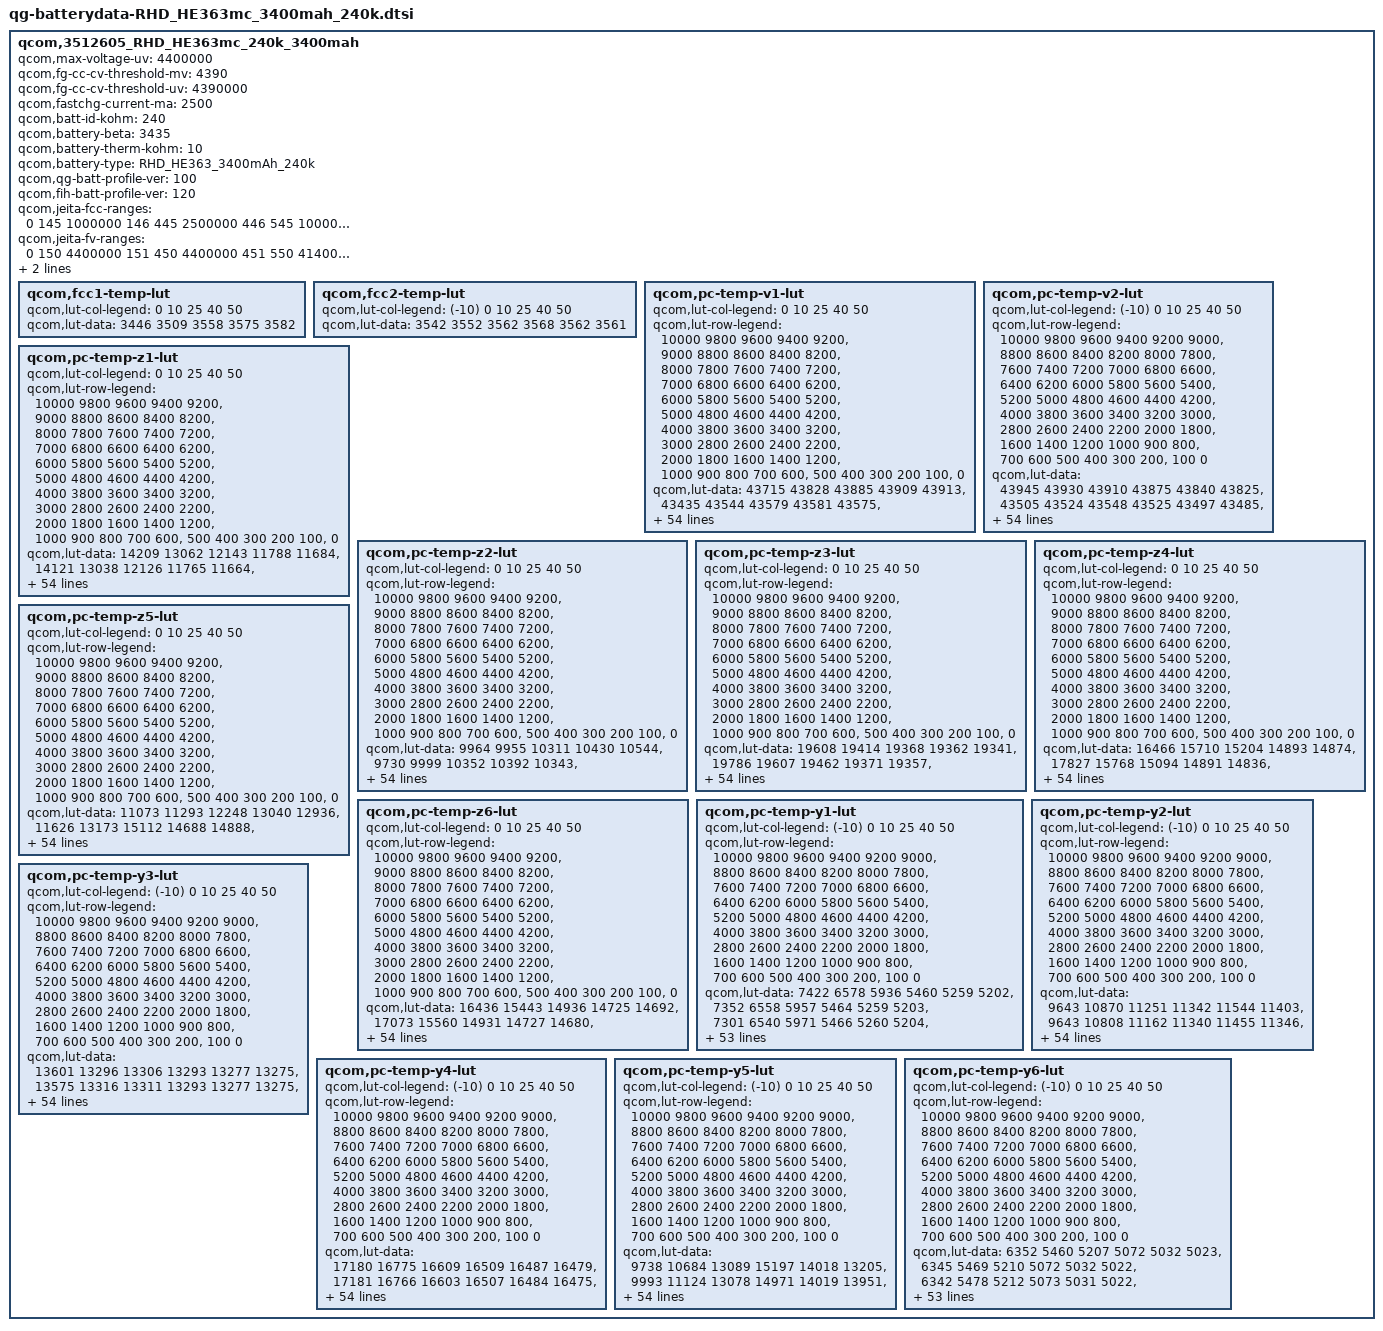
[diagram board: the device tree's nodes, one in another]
qcom,3512605_RHD_HE363mc_240k_3400mah {
	/* 3512605_FIH_HE363mc_3400mAh_averaged_MasterSlave_Jun25th2018 */
	qcom,max-voltage-uv = <4400000>;
	qcom,fg-cc-cv-threshold-mv = <4390>; // not use
	qcom,fg-cc-cv-threshold-uv = <4390000>; // not use
	qcom,fastchg-current-ma = <2500>;
	qcom,batt-id-kohm = <240>;
	qcom,battery-beta = <3435>;
	qcom,battery-therm-kohm = <10>;
	qcom,battery-type =
		"RHD_HE363_3400mAh_240k";
	qcom,qg-batt-profile-ver = <100>;
	qcom,fih-batt-profile-ver = <120>;

	qcom,jeita-fcc-ranges = <0   145   1000000
				 146 445  2500000
				 446 545  1000000
				 546 550  100000>;
	qcom,jeita-fv-ranges =  <0   150  4400000
				 151 450  4400000
				 451 550  4140000>;

	qcom,jeita-soft-thresholds = <0x257d 0xfb3>;
	qcom,jeita-hard-thresholds = <0x3733 0xbc2>;

	qcom,fcc1-temp-lut {
		qcom,lut-col-legend = <0 10 25 40 50>;
		qcom,lut-data = <3446 3509 3558 3575 3582>;
	};

	qcom,fcc2-temp-lut {
		qcom,lut-col-legend = <(-10) 0 10 25 40 50>;
		qcom,lut-data = <3542 3552 3562 3568 3562 3561>;
	};

	qcom,pc-temp-v1-lut {
		qcom,lut-col-legend = <0 10 25 40 50>;
		qcom,lut-row-legend = <10000 9800 9600 9400 9200>,
			<9000 8800 8600 8400 8200>,
			<8000 7800 7600 7400 7200>,
			<7000 6800 6600 6400 6200>,
			<6000 5800 5600 5400 5200>,
			<5000 4800 4600 4400 4200>,
			<4000 3800 3600 3400 3200>,
			<3000 2800 2600 2400 2200>,
			<2000 1800 1600 1400 1200>,
			<1000 900 800 700 600>,
			<500 400 300 200 100>,
			<0>;
		qcom,lut-data = <43715 43828 43885 43909 43913>,
			<43435 43544 43579 43581 43575>,
			<43142 43252 43304 43306 43301>,
			<42859 42997 43045 43054 43049>,
			<42605 42753 42799 42813 42810>,
			<42369 42511 42557 42575 42574>,
			<42142 42277 42319 42338 42340>,
			<41926 42049 42085 42104 42110>,
			<41715 41828 41855 41875 41881>,
			<41504 41612 41630 41649 41655>,
			<41297 41395 41408 41425 41432>,
			<41112 41189 41190 41205 41214>,
			<40953 41012 40985 40990 41000>,
			<40772 40854 40805 40787 40793>,
			<40486 40651 40625 40589 40591>,
			<40167 40344 40408 40396 40396>,
			<39972 40072 40172 40206 40208>,
			<39846 39933 39985 40027 40030>,
			<39732 39831 39843 39861 39861>,
			<39618 39708 39706 39703 39699>,
			<39506 39566 39567 39555 39549>,
			<39387 39418 39418 39408 39402>,
			<39260 39273 39212 39220 39219>,
			<39137 39119 38931 38968 38977>,
			<39022 38935 38736 38767 38776>,
			<38910 38719 38630 38643 38643>,
			<38795 38565 38547 38541 38535>,
			<38680 38471 38463 38441 38432>,
			<38577 38400 38387 38349 38338>,
			<38484 38341 38314 38267 38252>,
			<38404 38292 38243 38195 38175>,
			<38339 38247 38180 38130 38104>,
			<38284 38204 38129 38072 38043>,
			<38241 38164 38083 38019 37986>,
			<38209 38131 38043 37973 37935>,
			<38180 38099 38006 37933 37890>,
			<38152 38067 37968 37890 37840>,
			<38125 38038 37931 37841 37782>,
			<38087 37999 37886 37783 37716>,
			<38025 37931 37815 37708 37638>,
			<37944 37837 37717 37616 37546>,
			<37833 37730 37610 37509 37440>,
			<37691 37599 37485 37380 37313>,
			<37533 37442 37335 37232 37163>,
			<37372 37286 37178 37081 37011>,
			<37244 37172 37071 36978 36917>,
			<37201 37134 37043 36951 36890>,
			<37169 37107 37021 36931 36871>,
			<37144 37085 37003 36917 36857>,
			<37117 37061 36978 36889 36822>,
			<37005 36938 36834 36714 36622>,
			<36629 36559 36444 36313 36210>,
			<36076 36002 35883 35757 35650>,
			<35315 35240 35116 34998 34886>,
			<34135 34062 33929 33841 33713>,
			<30000 30000 30000 30000 30000>;
	};

	qcom,pc-temp-v2-lut {
		qcom,lut-col-legend = <(-10) 0 10 25 40 50>;
		qcom,lut-row-legend = <10000 9800 9600 9400 9200 9000>,
			<8800 8600 8400 8200 8000 7800>,
			<7600 7400 7200 7000 6800 6600>,
			<6400 6200 6000 5800 5600 5400>,
			<5200 5000 4800 4600 4400 4200>,
			<4000 3800 3600 3400 3200 3000>,
			<2800 2600 2400 2200 2000 1800>,
			<1600 1400 1200 1000 900 800>,
			<700 600 500 400 300 200>,
			<100 0>;
		qcom,lut-data = <43945 43930 43910 43875 43840 43825>,
			<43505 43524 43548 43525 43497 43485>,
			<43121 43169 43223 43209 43187 43177>,
			<42801 42872 42941 42934 42914 42906>,
			<42529 42621 42694 42691 42673 42666>,
			<42276 42378 42453 42453 42437 42430>,
			<42043 42138 42213 42216 42202 42196>,
			<41811 41905 41979 41983 41970 41964>,
			<41544 41681 41754 41755 41742 41736>,
			<41266 41463 41536 41530 41516 41511>,
			<41067 41257 41318 41306 41295 41290>,
			<40942 41066 41101 41085 41077 41072>,
			<40787 40865 40893 40875 40864 40860>,
			<40453 40645 40711 40689 40661 40654>,
			<40038 40407 40527 40505 40463 40453>,
			<39754 40123 40288 40292 40270 40262>,
			<39532 39795 40004 40061 40082 40078>,
			<39343 39560 39779 39871 39904 39901>,
			<39181 39418 39616 39726 39738 39733>,
			<39033 39289 39458 39576 39575 39568>,
			<38881 39124 39265 39390 39413 39411>,
			<38732 38949 39062 39187 39248 39252>,
			<38596 38794 38889 38987 39051 39057>,
			<38468 38651 38736 38785 38814 38816>,
			<38354 38524 38600 38619 38623 38621>,
			<38254 38410 38480 38493 38493 38492>,
			<38167 38307 38372 38385 38385 38385>,
			<38097 38208 38273 38286 38285 38284>,
			<38037 38114 38183 38197 38196 38193>,
			<37985 38033 38101 38116 38115 38110>,
			<37941 37963 38027 38042 38042 38036>,
			<37899 37903 37957 37973 37974 37967>,
			<37854 37855 37893 37910 37915 37907>,
			<37807 37815 37835 37850 37857 37848>,
			<37758 37778 37788 37794 37795 37783>,
			<37708 37745 37748 37740 37729 37712>,
			<37653 37707 37707 37684 37654 37629>,
			<37594 37663 37665 37627 37566 37521>,
			<37528 37610 37617 37563 37476 37414>,
			<37457 37550 37555 37486 37397 37329>,
			<37381 37476 37479 37401 37319 37252>,
			<37302 37367 37387 37317 37230 37166>,
			<37221 37247 37274 37199 37119 37056>,
			<37133 37131 37144 37072 36996 36930>,
			<37036 37020 36993 36918 36844 36783>,
			<36926 36930 36929 36874 36804 36748>,
			<36866 36889 36904 36864 36793 36737>,
			<36800 36848 36876 36846 36779 36724>,
			<36713 36787 36850 36815 36753 36697>,
			<36596 36693 36788 36740 36689 36624>,
			<36379 36483 36569 36467 36448 36355>,
			<36007 36065 36096 35965 35976 35871>,
			<35420 35439 35448 35305 35345 35230>,
			<34527 34559 34532 34370 34462 34345>,
			<33056 33144 33219 33097 33217 33037>,
			<28780 28512 28416 28775 29593 29393>;
	};

	qcom,pc-temp-z1-lut {
		qcom,lut-col-legend = <0 10 25 40 50>;
		qcom,lut-row-legend = <10000 9800 9600 9400 9200>,
			<9000 8800 8600 8400 8200>,
			<8000 7800 7600 7400 7200>,
			<7000 6800 6600 6400 6200>,
			<6000 5800 5600 5400 5200>,
			<5000 4800 4600 4400 4200>,
			<4000 3800 3600 3400 3200>,
			<3000 2800 2600 2400 2200>,
			<2000 1800 1600 1400 1200>,
			<1000 900 800 700 600>,
			<500 400 300 200 100>,
			<0>;
		qcom,lut-data = <14209 13062 12143 11788 11684>,
			<14121 13038 12126 11765 11664>,
			<14152 13003 12110 11758 11661>,
			<14179 12999 12103 11751 11657>,
			<14171 12997 12095 11748 11656>,
			<14146 12985 12088 11746 11655>,
			<14124 12970 12083 11745 11654>,
			<14103 12967 12079 11744 11654>,
			<14084 12967 12079 11743 11653>,
			<14066 12967 12079 11742 11652>,
			<14046 12966 12080 11741 11651>,
			<14026 12965 12084 11741 11651>,
			<14003 12959 12086 11741 11651>,
			<13985 12947 12080 11740 11651>,
			<13974 12937 12072 11740 11653>,
			<13963 12921 12067 11740 11653>,
			<13937 12910 12065 11740 11654>,
			<13879 12913 12065 11740 11655>,
			<13846 12922 12070 11742 11655>,
			<13846 12932 12076 11743 11656>,
			<13846 12949 12081 11745 11657>,
			<13849 12962 12085 11746 11658>,
			<13863 12972 12089 11748 11660>,
			<13880 12981 12093 11751 11662>,
			<13904 12982 12098 11754 11665>,
			<13925 12980 12103 11758 11668>,
			<13931 12982 12108 11761 11671>,
			<13933 12989 12116 11765 11674>,
			<13939 12997 12125 11769 11676>,
			<13981 13004 12130 11773 11679>,
			<14031 13011 12132 11775 11681>,
			<14049 13015 12135 11778 11683>,
			<14060 13019 12140 11780 11685>,
			<14068 13024 12145 11784 11687>,
			<14075 13031 12150 11787 11689>,
			<14081 13039 12155 11790 11692>,
			<14079 13051 12161 11793 11694>,
			<14070 13071 12168 11796 11696>,
			<14066 13083 12175 11799 11698>,
			<14051 13086 12180 11802 11701>,
			<14039 13090 12184 11805 11703>,
			<14039 13104 12189 11808 11705>,
			<14040 13128 12196 11809 11707>,
			<14022 13127 12202 11812 11709>,
			<13996 13114 12209 11816 11711>,
			<13987 13106 12215 11818 11713>,
			<14035 13108 12211 11819 11713>,
			<14074 13103 12210 11820 11713>,
			<14035 13103 12213 11822 11714>,
			<13970 13106 12217 11826 11718>,
			<13970 13118 12227 11833 11723>,
			<14020 13131 12238 11840 11730>,
			<13999 13164 12251 11850 11741>,
			<14043 13196 12281 11866 11754>,
			<14043 13196 12281 11866 11754>,
			<14043 13196 12281 11866 11754>;
	};

	qcom,pc-temp-z2-lut {
		qcom,lut-col-legend = <0 10 25 40 50>;
		qcom,lut-row-legend = <10000 9800 9600 9400 9200>,
			<9000 8800 8600 8400 8200>,
			<8000 7800 7600 7400 7200>,
			<7000 6800 6600 6400 6200>,
			<6000 5800 5600 5400 5200>,
			<5000 4800 4600 4400 4200>,
			<4000 3800 3600 3400 3200>,
			<3000 2800 2600 2400 2200>,
			<2000 1800 1600 1400 1200>,
			<1000 900 800 700 600>,
			<500 400 300 200 100>,
			<0>;
		qcom,lut-data = <9964 9955 10311 10430 10544>,
			<9730 9999 10352 10392 10343>,
			<9829 10040 10374 10515 10356>,
			<9882 10025 10348 10513 10510>,
			<9879 10010 10318 10470 10470>,
			<9869 9999 10298 10453 10444>,
			<9866 9989 10284 10470 10448>,
			<9865 9981 10277 10493 10452>,
			<9863 9968 10296 10503 10454>,
			<9857 9959 10333 10510 10461>,
			<9848 9952 10348 10517 10462>,
			<9838 9949 10355 10526 10432>,
			<9827 9977 10366 10531 10404>,
			<9818 10057 10404 10493 10387>,
			<9815 10091 10442 10436 10367>,
			<9814 10056 10433 10430 10377>,
			<9819 10026 10406 10440 10415>,
			<9837 10055 10402 10451 10438>,
			<9848 10105 10436 10477 10445>,
			<9848 10131 10470 10499 10453>,
			<9846 10142 10489 10507 10474>,
			<9844 10155 10504 10513 10508>,
			<9838 10182 10514 10534 10552>,
			<9835 10211 10521 10611 10665>,
			<9844 10220 10515 10649 10722>,
			<9862 10223 10482 10662 10682>,
			<9880 10229 10454 10670 10615>,
			<9903 10244 10458 10638 10546>,
			<9923 10258 10472 10582 10469>,
			<9940 10259 10471 10546 10436>,
			<9956 10258 10444 10504 10424>,
			<9968 10259 10427 10480 10419>,
			<9978 10267 10432 10491 10411>,
			<9990 10278 10442 10517 10400>,
			<10003 10289 10458 10550 10427>,
			<10016 10301 10487 10596 10512>,
			<9979 10314 10510 10637 10577>,
			<9875 10329 10525 10667 10617>,
			<9834 10346 10540 10698 10651>,
			<9757 10366 10564 10745 10682>,
			<9691 10387 10590 10795 10710>,
			<9722 10408 10604 10816 10718>,
			<9777 10429 10612 10820 10720>,
			<9789 10448 10624 10770 10718>,
			<9705 10557 10650 10707 10715>,
			<9578 10921 10723 10786 10735>,
			<9605 11029 10727 10748 10743>,
			<9616 11117 10727 10731 10738>,
			<9637 11167 10774 10793 10787>,
			<9637 11187 10874 10879 10937>,
			<9782 11256 10921 10801 10711>,
			<9669 10931 10941 10664 10482>,
			<9506 10665 10901 10576 10398>,
			<9327 10426 10830 10472 10297>,
			<9327 10426 10830 10472 10297>,
			<9327 10426 10830 10472 10297>;
	};

	qcom,pc-temp-z3-lut {
		qcom,lut-col-legend = <0 10 25 40 50>;
		qcom,lut-row-legend = <10000 9800 9600 9400 9200>,
			<9000 8800 8600 8400 8200>,
			<8000 7800 7600 7400 7200>,
			<7000 6800 6600 6400 6200>,
			<6000 5800 5600 5400 5200>,
			<5000 4800 4600 4400 4200>,
			<4000 3800 3600 3400 3200>,
			<3000 2800 2600 2400 2200>,
			<2000 1800 1600 1400 1200>,
			<1000 900 800 700 600>,
			<500 400 300 200 100>,
			<0>;
		qcom,lut-data = <19608 19414 19368 19362 19341>,
			<19786 19607 19462 19371 19357>,
			<19898 19749 19493 19394 19368>,
			<19953 19779 19536 19441 19420>,
			<19953 19788 19537 19442 19425>,
			<19939 19783 19537 19442 19425>,
			<19937 19773 19530 19439 19420>,
			<19942 19763 19521 19433 19411>,
			<19946 19753 19507 19424 19405>,
			<19951 19746 19490 19413 19399>,
			<19957 19739 19482 19406 19395>,
			<19957 19732 19479 19403 19386>,
			<19947 19717 19474 19400 19378>,
			<19937 19694 19455 19385 19372>,
			<19933 19687 19436 19368 19365>,
			<19929 19680 19440 19366 19362>,
			<19914 19664 19451 19366 19358>,
			<19869 19625 19453 19366 19355>,
			<19825 19571 19444 19364 19352>,
			<19791 19563 19436 19361 19350>,
			<19763 19589 19434 19359 19346>,
			<19755 19610 19432 19357 19343>,
			<19769 19617 19439 19359 19344>,
			<19782 19623 19466 19372 19350>,
			<19785 19631 19478 19379 19358>,
			<19788 19643 19458 19373 19366>,
			<19805 19648 19439 19367 19373>,
			<19854 19646 19442 19377 19379>,
			<19884 19642 19452 19402 19385>,
			<19893 19636 19458 19409 19387>,
			<19895 19629 19469 19402 19382>,
			<19889 19623 19475 19395 19376>,
			<19877 19619 19470 19391 19371>,
			<19862 19615 19461 19386 19365>,
			<19841 19610 19455 19381 19359>,
			<19811 19603 19451 19374 19352>,
			<19747 19597 19448 19371 19348>,
			<19644 19590 19445 19369 19346>,
			<19572 19583 19443 19368 19345>,
			<19464 19575 19440 19366 19345>,
			<19383 19565 19436 19364 19345>,
			<19377 19551 19432 19363 19344>,
			<19374 19533 19426 19362 19342>,
			<19360 19525 19423 19358 19342>,
			<19316 19480 19420 19351 19343>,
			<19271 19321 19395 19347 19335>,
			<19271 19311 19383 19340 19329>,
			<19270 19302 19376 19338 19328>,
			<19269 19296 19363 19327 19316>,
			<19269 19291 19351 19320 19311>,
			<19265 19298 19356 19339 19336>,
			<19268 19306 19354 19350 19347>,
			<19272 19306 19343 19354 19351>,
			<19294 19304 19340 19358 19351>,
			<19294 19304 19340 19358 19351>,
			<19294 19304 19340 19358 19351>;
	};

	qcom,pc-temp-z4-lut {
		qcom,lut-col-legend = <0 10 25 40 50>;
		qcom,lut-row-legend = <10000 9800 9600 9400 9200>,
			<9000 8800 8600 8400 8200>,
			<8000 7800 7600 7400 7200>,
			<7000 6800 6600 6400 6200>,
			<6000 5800 5600 5400 5200>,
			<5000 4800 4600 4400 4200>,
			<4000 3800 3600 3400 3200>,
			<3000 2800 2600 2400 2200>,
			<2000 1800 1600 1400 1200>,
			<1000 900 800 700 600>,
			<500 400 300 200 100>,
			<0>;
		qcom,lut-data = <16466 15710 15204 14893 14874>,
			<17827 15768 15094 14891 14836>,
			<17637 16170 15047 14832 14787>,
			<17350 15843 15149 14930 14864>,
			<17016 15516 15030 14881 14827>,
			<16608 15358 14944 14835 14792>,
			<16300 15240 14891 14803 14773>,
			<16066 15150 14856 14781 14760>,
			<15880 15080 14836 14773 14752>,
			<15740 15025 14821 14769 14745>,
			<15628 14980 14812 14763 14741>,
			<15519 14942 14806 14752 14736>,
			<15404 14897 14799 14745 14733>,
			<15339 14846 14790 14747 14730>,
			<15329 14833 14781 14750 14724>,
			<15323 14865 14774 14747 14719>,
			<15298 14894 14767 14736 14712>,
			<15218 14890 14758 14727 14706>,
			<15160 14879 14746 14721 14700>,
			<15145 14860 14737 14716 14696>,
			<15134 14817 14733 14714 14695>,
			<15117 14789 14731 14713 14695>,
			<15087 14785 14756 14730 14710>,
			<15064 14784 14857 14819 14794>,
			<15047 14809 14901 14867 14844>,
			<15031 14894 14899 14862 14828>,
			<15006 14932 14893 14849 14800>,
			<14954 14924 14873 14822 14775>,
			<14922 14911 14831 14775 14750>,
			<14911 14895 14799 14750 14734>,
			<14905 14872 14771 14739 14725>,
			<14900 14851 14753 14732 14718>,
			<14894 14832 14745 14723 14711>,
			<14888 14815 14739 14717 14706>,
			<14882 14800 14734 14714 14705>,
			<14875 14787 14729 14713 14706>,
			<14908 14773 14726 14712 14707>,
			<14993 14760 14723 14718 14717>,
			<15028 14751 14721 14724 14726>,
			<15105 14746 14723 14726 14726>,
			<15172 14743 14725 14727 14725>,
			<15162 14743 14723 14724 14722>,
			<15141 14744 14709 14712 14712>,
			<15130 14737 14702 14712 14711>,
			<15095 14756 14695 14714 14711>,
			<15050 14872 14677 14686 14686>,
			<15046 14877 14680 14681 14680>,
			<15041 14880 14674 14663 14661>,
			<15032 14879 14679 14655 14647>,
			<15020 14877 14685 14653 14642>,
			<15012 14870 14694 14660 14648>,
			<15039 14879 14708 14660 14650>,
			<15066 14891 14725 14660 14650>,
			<15080 14908 14736 14660 14652>,
			<15080 14908 14736 14660 14652>,
			<15080 14908 14736 14660 14652>;
	};

	qcom,pc-temp-z5-lut {
		qcom,lut-col-legend = <0 10 25 40 50>;
		qcom,lut-row-legend = <10000 9800 9600 9400 9200>,
			<9000 8800 8600 8400 8200>,
			<8000 7800 7600 7400 7200>,
			<7000 6800 6600 6400 6200>,
			<6000 5800 5600 5400 5200>,
			<5000 4800 4600 4400 4200>,
			<4000 3800 3600 3400 3200>,
			<3000 2800 2600 2400 2200>,
			<2000 1800 1600 1400 1200>,
			<1000 900 800 700 600>,
			<500 400 300 200 100>,
			<0>;
		qcom,lut-data = <11073 11293 12248 13040 12936>,
			<11626 13173 15112 14688 14888>,
			<12253 13406 16286 17076 17039>,
			<12794 13862 15715 17018 18322>,
			<13160 14338 16238 17244 19096>,
			<13461 14661 16698 17578 19666>,
			<13763 14957 17167 18300 19993>,
			<14076 15305 17440 18919 20113>,
			<14374 15704 17449 18701 19954>,
			<14661 16139 17432 18056 19621>,
			<14934 16716 17500 17899 19541>,
			<15139 17296 17699 18206 19155>,
			<15319 17765 17762 18422 18746>,
			<15431 18297 17069 17536 18392>,
			<15422 18482 16303 16259 17981>,
			<15364 18189 16608 16234 18046>,
			<15326 17627 17643 16790 18302>,
			<15180 16614 18607 17293 18551>,
			<15023 15400 19563 17668 18911>,
			<14751 15580 20258 18011 19244>,
			<14394 18533 20624 18321 19394>,
			<14356 22013 21036 18642 19495>,
			<15086 25098 23738 19140 19433>,
			<16042 28161 31845 20087 18899>,
			<16937 31403 35038 20500 18257>,
			<17988 35631 27606 18137 17133>,
			<20045 37188 20090 15468 16092>,
			<23915 34726 19466 16217 16513>,
			<26515 31385 19620 18825 18160>,
			<28549 29269 20572 20358 19505>,
			<30163 27532 23978 21151 20448>,
			<30330 26843 26485 21918 21374>,
			<29930 26694 27034 23208 22525>,
			<29255 26747 27433 24666 23621>,
			<27255 26899 28286 25368 24222>,
			<24525 27081 29575 25799 24639>,
			<21573 27294 30255 26002 24731>,
			<18282 27561 30616 25989 24078>,
			<16255 27622 30767 25812 23169>,
			<13537 27350 30295 24813 22465>,
			<11596 26791 29320 23181 21783>,
			<11581 24834 28429 22924 21217>,
			<11630 21427 27561 23244 20742>,
			<11564 21312 27321 22032 20374>,
			<11454 19655 27318 20180 20310>,
			<11383 12308 25296 21556 20472>,
			<11369 12087 21383 20083 19158>,
			<11362 11929 19637 20999 20514>,
			<11373 11839 17643 19424 20109>,
			<11398 11793 16165 18277 19525>,
			<11443 12002 16766 19731 22097>,
			<11398 11994 16228 19670 21942>,
			<11253 11873 14468 19436 21404>,
			<11215 11713 13916 19200 20154>,
			<11215 11713 13916 19200 20154>,
			<11215 11713 13916 19200 20154>;
	};

	qcom,pc-temp-z6-lut {
		qcom,lut-col-legend = <0 10 25 40 50>;
		qcom,lut-row-legend = <10000 9800 9600 9400 9200>,
			<9000 8800 8600 8400 8200>,
			<8000 7800 7600 7400 7200>,
			<7000 6800 6600 6400 6200>,
			<6000 5800 5600 5400 5200>,
			<5000 4800 4600 4400 4200>,
			<4000 3800 3600 3400 3200>,
			<3000 2800 2600 2400 2200>,
			<2000 1800 1600 1400 1200>,
			<1000 900 800 700 600>,
			<500 400 300 200 100>,
			<0>;
		qcom,lut-data = <16436 15443 14936 14725 14692>,
			<17073 15560 14931 14727 14680>,
			<17020 15787 14924 14713 14665>,
			<16932 15657 14989 14780 14724>,
			<16793 15521 14938 14760 14712>,
			<16594 15444 14899 14739 14698>,
			<16447 15383 14873 14724 14686>,
			<16340 15336 14852 14711 14676>,
			<16255 15299 14834 14702 14668>,
			<16192 15269 14819 14694 14663>,
			<16141 15246 14811 14687 14657>,
			<16085 15224 14807 14682 14651>,
			<16024 15194 14801 14676 14646>,
			<15975 15158 14785 14669 14640>,
			<15946 15147 14770 14661 14634>,
			<15922 15147 14769 14657 14629>,
			<15881 15147 14770 14653 14624>,
			<15814 15130 14768 14649 14620>,
			<15766 15098 14759 14645 14616>,
			<15744 15090 14751 14642 14613>,
			<15731 15089 14749 14640 14611>,
			<15731 15089 14748 14638 14609>,
			<15734 15091 14763 14647 14616>,
			<15738 15096 14822 14693 14658>,
			<15740 15113 14848 14718 14682>,
			<15743 15158 14840 14714 14680>,
			<15748 15177 14828 14708 14674>,
			<15756 15176 14819 14702 14669>,
			<15763 15172 14809 14695 14662>,
			<15770 15165 14802 14688 14655>,
			<15776 15152 14796 14681 14649>,
			<15775 15142 14791 14673 14642>,
			<15772 15134 14784 14667 14637>,
			<15767 15127 14778 14662 14631>,
			<15758 15120 14774 14658 14627>,
			<15747 15113 14771 14653 14623>,
			<15735 15108 14768 14652 14622>,
			<15722 15104 14766 14654 14625>,
			<15708 15101 14765 14656 14628>,
			<15693 15098 14765 14656 14628>,
			<15681 15096 14766 14656 14628>,
			<15675 15093 14764 14654 14627>,
			<15670 15088 14757 14650 14621>,
			<15660 15085 14753 14647 14621>,
			<15627 15073 14750 14645 14622>,
			<15586 15049 14732 14630 14607>,
			<15585 15046 14726 14625 14601>,
			<15582 15043 14720 14617 14593>,
			<15581 15043 14716 14607 14581>,
			<15578 15042 14715 14604 14576>,
			<15584 15048 14723 14617 14592>,
			<15607 15065 14732 14625 14601>,
			<15638 15083 14738 14629 14605>,
			<15675 15107 14749 14635 14610>,
			<15675 15107 14749 14635 14610>,
			<15675 15107 14749 14635 14610>;
	};

	qcom,pc-temp-y1-lut {
		qcom,lut-col-legend = <(-10) 0 10 25 40 50>;
		qcom,lut-row-legend = <10000 9800 9600 9400 9200 9000>,
			<8800 8600 8400 8200 8000 7800>,
			<7600 7400 7200 7000 6800 6600>,
			<6400 6200 6000 5800 5600 5400>,
			<5200 5000 4800 4600 4400 4200>,
			<4000 3800 3600 3400 3200 3000>,
			<2800 2600 2400 2200 2000 1800>,
			<1600 1400 1200 1000 900 800>,
			<700 600 500 400 300 200>,
			<100 0>;
		qcom,lut-data = <7422 6578 5936 5460 5259 5202>,
			<7352 6558 5957 5464 5259 5203>,
			<7301 6540 5971 5466 5260 5204>,
			<7265 6526 5980 5467 5260 5206>,
			<7243 6517 5984 5467 5260 5206>,
			<7232 6514 5984 5466 5260 5207>,
			<7242 6517 5977 5463 5260 5207>,
			<7254 6521 5968 5461 5260 5207>,
			<7248 6518 5964 5461 5258 5207>,
			<7234 6512 5962 5460 5255 5207>,
			<7225 6508 5961 5460 5255 5207>,
			<7211 6506 5962 5460 5257 5206>,
			<7202 6504 5962 5459 5258 5206>,
			<7204 6520 5961 5456 5258 5205>,
			<7208 6542 5960 5454 5258 5205>,
			<7213 6544 5962 5456 5258 5204>,
			<7225 6535 5966 5462 5259 5204>,
			<7230 6531 5967 5466 5259 5204>,
			<7218 6531 5966 5467 5261 5205>,
			<7205 6531 5966 5467 5263 5206>,
			<7217 6532 5967 5466 5263 5207>,
			<7246 6533 5968 5465 5263 5209>,
			<7257 6532 5968 5465 5264 5209>,
			<7255 6528 5967 5467 5264 5211>,
			<7254 6526 5967 5470 5265 5212>,
			<7249 6531 5968 5473 5265 5213>,
			<7239 6537 5969 5476 5266 5213>,
			<7229 6536 5974 5478 5268 5214>,
			<7213 6530 5984 5481 5271 5214>,
			<7202 6526 5987 5484 5273 5216>,
			<7191 6526 5984 5489 5275 5219>,
			<7183 6529 5982 5493 5277 5221>,
			<7187 6527 5987 5495 5280 5222>,
			<7198 6524 5996 5497 5283 5222>,
			<7203 6527 5998 5499 5284 5223>,
			<7205 6539 5998 5500 5285 5227>,
			<7205 6544 5999 5502 5286 5229>,
			<7194 6542 6003 5508 5289 5230>,
			<7180 6538 6007 5512 5292 5231>,
			<7182 6533 6002 5512 5293 5233>,
			<7192 6530 5996 5511 5293 5235>,
			<7210 6535 6001 5515 5296 5238>,
			<7218 6540 5998 5518 5298 5238>,
			<7175 6543 5999 5519 5297 5239>,
			<7202 6543 6011 5522 5301 5241>,
			<7226 6566 6012 5523 5305 5241>,
			<7188 6544 6017 5529 5304 5242>,
			<7196 6545 6011 5530 5306 5241>,
			<7220 6561 6014 5533 5306 5243>,
			<7214 6550 6025 5536 5305 5243>,
			<7214 6556 6027 5539 5305 5245>,
			<7191 6581 6042 5545 5312 5247>,
			<7200 6565 6056 5559 5321 5253>,
			<7261 6581 6077 5580 5330 5262>,
			<7261 6581 6077 5580 5330 5262>,
			<7261 6581 6077 5580 5330 5262>;
	};

	qcom,pc-temp-y2-lut {
		qcom,lut-col-legend = <(-10) 0 10 25 40 50>;
		qcom,lut-row-legend = <10000 9800 9600 9400 9200 9000>,
			<8800 8600 8400 8200 8000 7800>,
			<7600 7400 7200 7000 6800 6600>,
			<6400 6200 6000 5800 5600 5400>,
			<5200 5000 4800 4600 4400 4200>,
			<4000 3800 3600 3400 3200 3000>,
			<2800 2600 2400 2200 2000 1800>,
			<1600 1400 1200 1000 900 800>,
			<700 600 500 400 300 200>,
			<100 0>;
		qcom,lut-data = <9643 10870 11251 11342 11544 11403>,
			<9643 10808 11162 11340 11455 11346>,
			<9643 10733 11076 11320 11348 11278>,
			<9777 10660 10997 11288 11246 11211>,
			<9919 10601 10927 11248 11171 11155>,
			<9999 10569 10868 11203 11143 11123>,
			<10167 10553 10818 11138 11147 11102>,
			<10317 10544 10776 11082 11155 11088>,
			<10318 10549 10742 11050 11150 11078>,
			<10304 10562 10714 11020 11135 11064>,
			<10322 10570 10698 11014 11117 11042>,
			<10479 10573 10687 11001 11059 10996>,
			<10586 10578 10682 10983 11025 10970>,
			<10572 10626 10690 10958 11021 11000>,
			<10534 10692 10709 10937 11018 11037>,
			<10369 10718 10736 10939 11021 11033>,
			<9917 10731 10780 10957 11035 11012>,
			<9714 10746 10816 10986 11053 11009>,
			<9704 10768 10840 11048 11076 11013>,
			<9698 10791 10865 11095 11109 11021>,
			<9690 10811 10903 11104 11191 11106>,
			<9682 10831 10949 11110 11292 11237>,
			<9678 10857 10995 11131 11303 11257>,
			<9675 10891 11043 11185 11273 11242>,
			<9673 10915 11083 11220 11259 11236>,
			<9672 10926 11115 11230 11294 11270>,
			<9671 10936 11136 11239 11333 11317>,
			<9670 10959 11141 11256 11339 11349>,
			<9668 11002 11143 11278 11340 11387>,
			<9666 11034 11144 11287 11333 11428>,
			<9665 11058 11139 11299 11324 11481>,
			<9663 11070 11137 11306 11320 11520>,
			<9662 11061 11141 11301 11381 11540>,
			<9660 11037 11144 11292 11467 11551>,
			<9659 11005 11140 11283 11452 11546>,
			<9658 10957 11132 11272 11366 11513>,
			<9657 10910 11122 11259 11325 11473>,
			<9656 10871 11100 11238 11328 11413>,
			<9655 10833 11080 11224 11331 11371>,
			<9654 10795 11081 11328 11329 11379>,
			<9653 10745 11082 11448 11334 11400>,
			<9653 10339 11040 11267 11371 11403>,
			<9652 9859 11018 11334 11372 11396>,
			<9652 9761 11018 11319 11329 11412>,
			<9652 9708 11066 11342 11345 11387>,
			<9652 9677 10902 11251 11353 11245>,
			<9652 9669 10849 11192 11313 11191>,
			<9651 9664 10789 11206 11260 11139>,
			<9652 9661 10702 11195 11228 11117>,
			<9651 9658 10651 11176 11192 11094>,
			<9651 9656 10586 11152 11202 11024>,
			<9651 9654 10492 11055 11145 10972>,
			<9651 9652 10364 10967 11016 10861>,
			<9650 9651 10216 10827 10857 10684>,
			<9650 9651 10216 10827 10857 10684>,
			<9650 9651 10216 10827 10857 10684>;
	};

	qcom,pc-temp-y3-lut {
		qcom,lut-col-legend = <(-10) 0 10 25 40 50>;
		qcom,lut-row-legend = <10000 9800 9600 9400 9200 9000>,
			<8800 8600 8400 8200 8000 7800>,
			<7600 7400 7200 7000 6800 6600>,
			<6400 6200 6000 5800 5600 5400>,
			<5200 5000 4800 4600 4400 4200>,
			<4000 3800 3600 3400 3200 3000>,
			<2800 2600 2400 2200 2000 1800>,
			<1600 1400 1200 1000 900 800>,
			<700 600 500 400 300 200>,
			<100 0>;
		qcom,lut-data = <13601 13296 13306 13293 13277 13275>,
			<13575 13316 13311 13293 13277 13275>,
			<13560 13336 13315 13293 13278 13276>,
			<13553 13354 13318 13293 13278 13277>,
			<13551 13369 13319 13294 13279 13278>,
			<13552 13381 13320 13294 13279 13278>,
			<13561 13390 13318 13294 13280 13279>,
			<13571 13398 13316 13294 13280 13279>,
			<13571 13407 13322 13294 13280 13280>,
			<13570 13415 13334 13296 13280 13280>,
			<13564 13422 13343 13296 13280 13280>,
			<13537 13430 13349 13296 13280 13280>,
			<13515 13433 13355 13297 13280 13280>,
			<13511 13433 13362 13301 13284 13280>,
			<13507 13431 13367 13307 13288 13279>,
			<13493 13423 13367 13310 13288 13281>,
			<13457 13403 13365 13313 13287 13284>,
			<13442 13394 13362 13315 13287 13286>,
			<13442 13393 13357 13315 13290 13285>,
			<13442 13392 13351 13315 13293 13285>,
			<13438 13387 13344 13314 13295 13288>,
			<13429 13377 13338 13311 13297 13293>,
			<13419 13368 13331 13306 13295 13291>,
			<13405 13358 13324 13300 13286 13281>,
			<13393 13353 13320 13297 13280 13275>,
			<13386 13354 13318 13296 13278 13275>,
			<13382 13355 13317 13295 13277 13275>,
			<13386 13351 13317 13295 13277 13274>,
			<13401 13338 13318 13295 13278 13274>,
			<13419 13333 13319 13295 13278 13274>,
			<13444 13331 13320 13295 13279 13275>,
			<13473 13331 13321 13296 13280 13276>,
			<13501 13330 13320 13296 13280 13276>,
			<13530 13329 13319 13296 13280 13276>,
			<13568 13332 13320 13296 13280 13275>,
			<13619 13343 13321 13296 13280 13276>,
			<13682 13352 13322 13297 13280 13276>,
			<13765 13357 13324 13298 13279 13274>,
			<13868 13361 13325 13298 13278 13273>,
			<13988 13365 13323 13290 13278 13274>,
			<14134 13371 13320 13281 13278 13274>,
			<14311 13353 13323 13295 13277 13276>,
			<14511 13349 13321 13289 13278 13276>,
			<14547 13358 13322 13290 13279 13276>,
			<14735 13378 13303 13284 13278 13274>,
			<15054 13384 13317 13286 13279 13277>,
			<15236 13430 13318 13293 13281 13279>,
			<15396 13501 13322 13297 13285 13284>,
			<15540 13580 13344 13299 13287 13286>,
			<15702 13710 13360 13305 13291 13287>,
			<15850 13875 13367 13299 13285 13283>,
			<16032 14110 13372 13299 13286 13283>,
			<16286 14603 13396 13311 13293 13288>,
			<17209 15267 13440 13318 13295 13291>,
			<17209 15267 13440 13318 13295 13291>,
			<17209 15267 13440 13318 13295 13291>;
	};

	qcom,pc-temp-y4-lut {
		qcom,lut-col-legend = <(-10) 0 10 25 40 50>;
		qcom,lut-row-legend = <10000 9800 9600 9400 9200 9000>,
			<8800 8600 8400 8200 8000 7800>,
			<7600 7400 7200 7000 6800 6600>,
			<6400 6200 6000 5800 5600 5400>,
			<5200 5000 4800 4600 4400 4200>,
			<4000 3800 3600 3400 3200 3000>,
			<2800 2600 2400 2200 2000 1800>,
			<1600 1400 1200 1000 900 800>,
			<700 600 500 400 300 200>,
			<100 0>;
		qcom,lut-data = <17180 16775 16609 16509 16487 16479>,
			<17181 16766 16603 16507 16484 16475>,
			<17202 16763 16602 16507 16482 16471>,
			<17229 16764 16606 16508 16481 16468>,
			<17252 16769 16612 16509 16480 16466>,
			<17260 16774 16621 16511 16480 16466>,
			<17267 16783 16638 16516 16482 16466>,
			<17269 16796 16653 16521 16484 16468>,
			<17244 16818 16655 16526 16487 16470>,
			<17206 16851 16657 16531 16492 16472>,
			<17244 16878 16661 16538 16497 16476>,
			<17592 16898 16677 16549 16504 16481>,
			<17829 16925 16699 16561 16509 16486>,
			<17563 17005 16748 16574 16512 16492>,
			<17170 17087 16798 16589 16514 16499>,
			<17107 17040 16808 16602 16521 16504>,
			<17114 16854 16812 16616 16535 16507>,
			<17118 16778 16810 16638 16550 16513>,
			<17112 16779 16793 16689 16566 16526>,
			<17102 16780 16765 16723 16586 16544>,
			<17084 16760 16713 16713 16621 16573>,
			<17055 16720 16643 16688 16660 16605>,
			<17031 16702 16608 16642 16644 16595>,
			<17008 16694 16588 16555 16545 16524>,
			<16993 16686 16577 16508 16490 16483>,
			<16987 16673 16571 16497 16483 16477>,
			<16983 16661 16567 16492 16480 16475>,
			<16979 16663 16563 16493 16481 16476>,
			<16976 16671 16560 16495 16483 16479>,
			<16973 16673 16558 16498 16487 16483>,
			<16967 16667 16558 16503 16494 16490>,
			<16963 16662 16559 16508 16503 16497>,
			<16967 16667 16558 16514 16516 16510>,
			<16975 16676 16556 16519 16528 16523>,
			<16980 16677 16556 16519 16529 16524>,
			<16983 16672 16557 16515 16524 16523>,
			<16984 16670 16558 16510 16515 16519>,
			<16985 16677 16559 16500 16490 16493>,
			<16986 16690 16560 16492 16469 16469>,
			<16989 16700 16565 16497 16470 16469>,
			<16996 16712 16570 16503 16473 16471>,
			<17006 16757 16566 16490 16480 16476>,
			<17014 16784 16569 16497 16479 16476>,
			<16996 16762 16554 16493 16478 16475>,
			<16995 16764 16576 16487 16458 16451>,
			<17032 16820 16570 16496 16468 16465>,
			<17063 16839 16588 16499 16482 16478>,
			<17100 16870 16614 16516 16498 16498>,
			<17143 16941 16647 16546 16525 16530>,
			<17187 17030 16716 16568 16546 16544>,
			<17197 17079 16745 16543 16505 16489>,
			<17181 17088 16729 16546 16489 16479>,
			<17178 17134 16788 16589 16505 16492>,
			<17452 17284 16907 16707 16561 16552>,
			<17452 17284 16907 16707 16561 16552>,
			<17452 17284 16907 16707 16561 16552>;
	};

	qcom,pc-temp-y5-lut {
		qcom,lut-col-legend = <(-10) 0 10 25 40 50>;
		qcom,lut-row-legend = <10000 9800 9600 9400 9200 9000>,
			<8800 8600 8400 8200 8000 7800>,
			<7600 7400 7200 7000 6800 6600>,
			<6400 6200 6000 5800 5600 5400>,
			<5200 5000 4800 4600 4400 4200>,
			<4000 3800 3600 3400 3200 3000>,
			<2800 2600 2400 2200 2000 1800>,
			<1600 1400 1200 1000 900 800>,
			<700 600 500 400 300 200>,
			<100 0>;
		qcom,lut-data = <9738 10684 13089 15197 14018 13205>,
			<9993 11124 13078 14971 14019 13951>,
			<10561 11583 12978 14685 13994 14531>,
			<11244 12018 12816 14396 13949 14939>,
			<11847 12383 12615 14161 13888 15170>,
			<12200 12631 12389 14019 13816 15214>,
			<12857 12785 11978 13666 13730 15014>,
			<13429 12930 11678 13335 13620 14747>,
			<13251 13143 11859 13229 13454 14557>,
			<12773 13394 12300 13085 13223 14354>,
			<12591 13602 12567 12913 12977 14112>,
			<12633 13795 12728 12595 12678 13821>,
			<12828 14069 12865 12434 12542 13520>,
			<14329 14792 12970 12537 12957 13150>,
			<16275 15568 13100 12701 13478 12860>,
			<15708 15673 13644 12863 13376 13008>,
			<12713 15557 14844 13109 12931 13527>,
			<11399 15565 15551 13325 12783 13686>,
			<11432 15906 15941 13479 12925 13343>,
			<11469 16181 16138 13712 13187 13059>,
			<11437 15953 16098 14959 13882 13666>,
			<11334 15365 15980 16687 14906 14753>,
			<11244 14768 15696 16948 15397 14903>,
			<11124 14038 14913 16828 15621 14637>,
			<10997 13709 14432 16796 15641 14502>,
			<10836 13928 14344 16933 15198 14814>,
			<10697 14191 14341 17070 14791 15169>,
			<10683 13906 14435 17044 14896 15084>,
			<10693 12961 14658 16927 15114 14785>,
			<10716 12529 14934 16916 15359 14739>,
			<10859 12460 15273 17122 15666 15171>,
			<10991 12437 15401 17338 15962 15479>,
			<10981 12382 15224 17595 16174 15399>,
			<10945 12310 15113 17916 16384 15259>,
			<10938 12467 15293 18160 16843 15512>,
			<10993 13249 15632 18397 17752 16638>,
			<11036 13892 15899 18804 18121 17166>,
			<11083 14279 16180 19874 17888 17018>,
			<11143 14536 16372 20678 17512 16773>,
			<11135 14669 15828 17148 17063 16422>,
			<11103 14908 15042 12895 16452 16106>,
			<11118 13000 15332 18537 15560 16621>,
			<11192 11680 14730 15799 15517 16289>,
			<11093 11517 15200 16161 16120 16010>,
			<11185 11453 12525 13625 17110 17494>,
			<11183 11084 13389 13740 15926 15700>,
			<11254 11204 13111 15745 15233 15147>,
			<11431 11469 13002 16139 15586 15820>,
			<11561 11471 14698 15121 15097 15080>,
			<12008 11790 15296 15769 15219 14769>,
			<12077 12069 15273 15089 14698 15296>,
			<11879 11862 15278 15221 16169 15924>,
			<11420 11624 15314 17281 18372 17829>,
			<10772 11405 14994 17029 17928 18249>,
			<10772 11405 14994 17029 17928 18249>,
			<10772 11405 14994 17029 17928 18249>;
	};

	qcom,pc-temp-y6-lut {
		qcom,lut-col-legend = <(-10) 0 10 25 40 50>;
		qcom,lut-row-legend = <10000 9800 9600 9400 9200 9000>,
			<8800 8600 8400 8200 8000 7800>,
			<7600 7400 7200 7000 6800 6600>,
			<6400 6200 6000 5800 5600 5400>,
			<5200 5000 4800 4600 4400 4200>,
			<4000 3800 3600 3400 3200 3000>,
			<2800 2600 2400 2200 2000 1800>,
			<1600 1400 1200 1000 900 800>,
			<700 600 500 400 300 200>,
			<100 0>;
		qcom,lut-data = <6352 5460 5207 5072 5032 5023>,
			<6345 5469 5210 5072 5032 5022>,
			<6342 5478 5212 5073 5031 5022>,
			<6342 5487 5215 5073 5031 5021>,
			<6343 5494 5217 5074 5032 5022>,
			<6344 5500 5220 5075 5032 5022>,
			<6348 5505 5221 5076 5033 5022>,
			<6350 5510 5223 5078 5034 5023>,
			<6335 5518 5228 5080 5035 5024>,
			<6303 5530 5234 5082 5037 5026>,
			<6303 5539 5241 5085 5038 5027>,
			<6364 5547 5249 5088 5040 5028>,
			<6405 5556 5258 5092 5042 5030>,
			<6339 5576 5276 5098 5045 5031>,
			<6232 5595 5292 5107 5049 5033>,
			<6186 5577 5294 5113 5052 5036>,
			<6159 5513 5294 5119 5055 5039>,
			<6150 5486 5292 5127 5059 5042>,
			<6150 5487 5283 5142 5066 5046>,
			<6150 5487 5270 5151 5073 5051>,
			<6149 5480 5251 5147 5085 5061>,
			<6148 5465 5227 5137 5096 5073>,
			<6149 5456 5212 5120 5091 5069>,
			<6153 5449 5203 5091 5056 5040>,
			<6159 5447 5197 5076 5035 5024>,
			<6170 5448 5195 5072 5032 5022>,
			<6185 5449 5194 5071 5030 5022>,
			<6203 5450 5195 5071 5031 5022>,
			<6225 5451 5196 5072 5032 5023>,
			<6249 5452 5198 5073 5033 5024>,
			<6277 5455 5200 5075 5036 5027>,
			<6308 5459 5203 5077 5039 5030>,
			<6342 5465 5204 5080 5044 5034>,
			<6382 5474 5205 5082 5048 5037>,
			<6427 5484 5207 5082 5048 5037>,
			<6480 5498 5210 5082 5047 5037>,
			<6542 5515 5213 5081 5044 5036>,
			<6616 5532 5216 5080 5037 5028>,
			<6704 5552 5220 5078 5030 5021>,
			<6805 5576 5222 5074 5030 5021>,
			<6922 5605 5224 5070 5031 5022>,
			<7061 5628 5229 5076 5033 5025>,
			<7213 5662 5232 5075 5034 5025>,
			<7239 5671 5231 5075 5034 5025>,
			<7382 5725 5230 5070 5028 5017>,
			<7624 5832 5247 5075 5032 5023>,
			<7761 5917 5259 5082 5037 5028>,
			<7889 6021 5276 5089 5045 5038>,
			<8008 6140 5311 5100 5055 5048>,
			<8132 6298 5355 5111 5063 5053>,
			<8246 6467 5386 5101 5047 5035>,
			<8380 6675 5409 5104 5044 5032>,
			<8577 7078 5492 5129 5055 5041>,
			<9425 7619 5644 5173 5074 5062>,
			<9425 7619 5644 5173 5074 5062>,
			<9425 7619 5644 5173 5074 5062>;
	};

};
